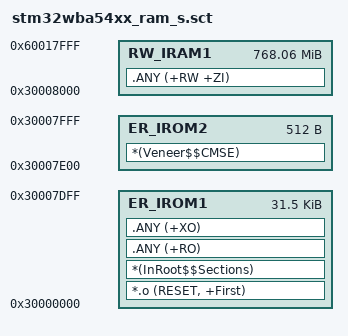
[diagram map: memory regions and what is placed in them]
; *************************************************************
; *** Scatter-Loading Description File generated by uVision ***
; *************************************************************

LR_IROM1 0x30000000 0x00007E00  {    ; load region size_region
  ER_IROM1 0x30000000 0x00007E00  {  ; load address = execution address
   *.o (RESET, +First)
   *(InRoot$$Sections)
   .ANY (+RO)
   .ANY (+XO)
  }
  RW_IRAM1 0x30008000 0x30010000  {  ; RW data
   .ANY (+RW +ZI)
  }
}

LR_IROM2 0x30007E00 0x00000200  {    ; load region size_region
  ER_IROM2 0x30007E00 0x00000200  {  ; load address = execution address
   *(Veneer$$CMSE)                   ; check with partition.h
  }
}
